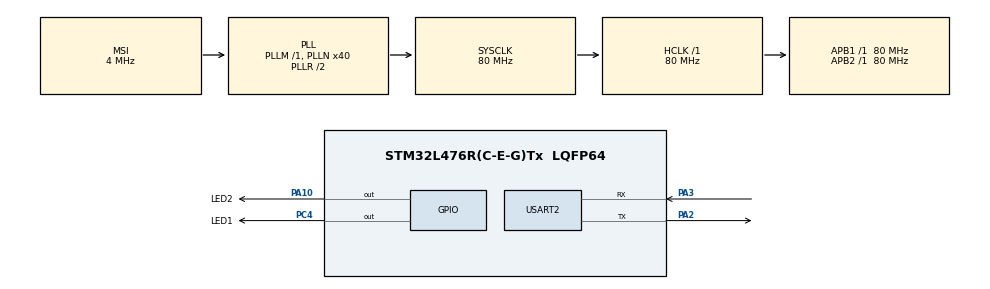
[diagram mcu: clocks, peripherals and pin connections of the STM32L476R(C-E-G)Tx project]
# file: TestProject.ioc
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FREERTOS.Tasks01=defaultTask,24,128,StartDefaultTask,Default,NULL,Dynamic,NULL,NULL;Task2,24,128,Task2_init,Default,NULL,Dynamic,NULL,NULL
FREERTOS.configUSE_NEWLIB_REENTRANT=1
Mcu.Family=STM32L4
Mcu.Name=STM32L476R(C-E-G)Tx
Mcu.Package=LQFP64
NVIC.PriorityGroup=NVIC_PRIORITYGROUP_4
NVIC.TIM6_DAC_IRQn=true\:15\:0\:false\:false\:true\:false\:false\:true\:true
NVIC.TimeBase=TIM6_DAC_IRQn
NVIC.TimeBaseIP=TIM6
PA10.GPIO_Label=LED2
PA10.Signal=GPIO_Output
PA13\ (JTMS-SWDIO).Mode=Serial_Wire
PA13\ (JTMS-SWDIO).Signal=SYS_JTMS-SWDIO
PA14\ (JTCK-SWCLK).Mode=Serial_Wire
PA14\ (JTCK-SWCLK).Signal=SYS_JTCK-SWCLK
PA2.Mode=Asynchronous
PA2.Signal=USART2_TX
PA3.Mode=Asynchronous
PA3.Signal=USART2_RX
PC4.GPIO_Label=LED1
PC4.Signal=GPIO_Output
ProjectManager.HeapSize=0x200
ProjectManager.StackSize=0x400
ProjectManager.TargetToolchain=STM32CubeIDE
RCC.AHBFreq_Value=80000000
RCC.APB1Freq_Value=80000000
RCC.APB1TimFreq_Value=80000000
RCC.APB2Freq_Value=80000000
RCC.APB2TimFreq_Value=80000000
RCC.CortexFreq_Value=80000000
RCC.HCLKFreq_Value=80000000
RCC.HSI_VALUE=16000000
RCC.LSE_VALUE=32768
RCC.MSI_VALUE=4000000
RCC.PLLN=40
RCC.SYSCLKFreq_VALUE=80000000
RCC.SYSCLKSource=RCC_SYSCLKSOURCE_PLLCLK
RCC.VCOOutputFreq_Value=160000000
USART2.VirtualMode-Asynchronous=VM_ASYNC
VP_FREERTOS_VS_CMSIS_V2.Mode=CMSIS_V2
VP_SYS_VS_tim6.Mode=TIM6
board=custom

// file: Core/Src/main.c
/* USER CODE BEGIN Header */
/**
  ******************************************************************************
  * @file           : main.c
  * @brief          : Main program body
  ******************************************************************************
  * @attention
  *
  * Copyright (c) 2024 STMicroelectronics.
  * All rights reserved.
  *
  * This software is licensed under terms that can be found in the LICENSE file
  * in the root directory of this software component.
  * If no LICENSE file comes with this software, it is provided AS-IS.
  *
  ******************************************************************************
  */
/* USER CODE END Header */
#include "main.h"
#include "cmsis_os.h"

UART_HandleTypeDef huart2;

/* Definitions for defaultTask */
osThreadId_t defaultTaskHandle;
const osThreadAttr_t defaultTask_attributes = {
  .name = "defaultTask",
  .stack_size = 128 * 4,
  .priority = (osPriority_t) osPriorityNormal,
};
/* Definitions for Task2 */
osThreadId_t Task2Handle;
const osThreadAttr_t Task2_attributes = {
  .name = "Task2",
  .stack_size = 128 * 4,
  .priority = (osPriority_t) osPriorityAboveNormal,
};

/* Definition for Task3 */
osThreadId_t Task3Handle;
const osThreadAttr_t Task3_attributes = {
	.name = "Task3",
	.stack_size = 128 * 4,
	.priority = (osPriority_t) osPriorityBelowNormal,
};

void SystemClock_Config(void);
static void MX_GPIO_Init(void);
static void MX_USART2_UART_Init(void);
void StartDefaultTask(void *argument);
void Task2_init(void *argument);
void Task3_init(void *argument);

/* USER CODE BEGIN 0 */
uint8_t message_deftask[] = "Deftask says Hello\r\n";
uint8_t message_task2[] = "Task1 says Hello\r\n";
uint8_t message_task3[] = "Task2 says Hello\r\n";

void send_deftask(void)
{
	HAL_UART_Transmit(&huart2, message_deftask, sizeof(message_deftask), HAL_MAX_DELAY);
}

void send_task2(void)
{
	HAL_UART_Transmit(&huart2, message_task2, sizeof(message_task2), HAL_MAX_DELAY);
}

void send_task3(void)
{
	HAL_UART_Transmit(&huart2, message_task3, sizeof(message_task3), HAL_MAX_DELAY);
}

/* USER CODE END 0 */

int main(void)
{

  /* MCU Configuration--------------------------------------------------------*/

  /* Reset of all peripherals, Initializes the Flash interface and the Systick. */
  HAL_Init();

  /* USER CODE BEGIN Init */
printf("Starting...");
  /* USER CODE END Init */

  /* Configure the system clock */
  SystemClock_Config();

  /* Initialize all configured peripherals */
  MX_GPIO_Init();
  MX_USART2_UART_Init();

  /* Init scheduler */
  osKernelInitialize();

  /* Create the thread(s) */
  /* creation of defaultTask */
  defaultTaskHandle = osThreadNew(StartDefaultTask, NULL, &defaultTask_attributes);

  /* creation of Task2 */
  Task2Handle = osThreadNew(Task2_init, NULL, &Task2_attributes);

  /* creation of Task3 */
  Task3Handle = osThreadNew(Task3_init , NULL, &Task3_attributes);

  /* Start scheduler */
  osKernelStart();

  /* We should never get here as control is now taken by the scheduler */
  /* Infinite loop */
  while (1)
  {

  }
}

void SystemClock_Config(void)
{
  RCC_OscInitTypeDef RCC_OscInitStruct = {0};
  RCC_ClkInitTypeDef RCC_ClkInitStruct = {0};

  /** Configure the main internal regulator output voltage
  */
  if (HAL_PWREx_ControlVoltageScaling(PWR_REGULATOR_VOLTAGE_SCALE1) != HAL_OK)
  {
    Error_Handler();
  }

  /** Initializes the RCC Oscillators according to the specified parameters
  * in the RCC_OscInitTypeDef structure.
  */
  RCC_OscInitStruct.OscillatorType = RCC_OSCILLATORTYPE_MSI;
  RCC_OscInitStruct.MSIState = RCC_MSI_ON;
  RCC_OscInitStruct.MSICalibrationValue = 0;
  RCC_OscInitStruct.MSIClockRange = RCC_MSIRANGE_6;
  RCC_OscInitStruct.PLL.PLLState = RCC_PLL_ON;
  RCC_OscInitStruct.PLL.PLLSource = RCC_PLLSOURCE_MSI;
  RCC_OscInitStruct.PLL.PLLM = 1;
  RCC_OscInitStruct.PLL.PLLN = 40;
  RCC_OscInitStruct.PLL.PLLP = RCC_PLLP_DIV7;
  RCC_OscInitStruct.PLL.PLLQ = RCC_PLLQ_DIV2;
  RCC_OscInitStruct.PLL.PLLR = RCC_PLLR_DIV2;
  if (HAL_RCC_OscConfig(&RCC_OscInitStruct) != HAL_OK)
  {
    Error_Handler();
  }

  /** Initializes the CPU, AHB and APB buses clocks
  */
  RCC_ClkInitStruct.ClockType = RCC_CLOCKTYPE_HCLK|RCC_CLOCKTYPE_SYSCLK
                              |RCC_CLOCKTYPE_PCLK1|RCC_CLOCKTYPE_PCLK2;
  RCC_ClkInitStruct.SYSCLKSource = RCC_SYSCLKSOURCE_PLLCLK;
  RCC_ClkInitStruct.AHBCLKDivider = RCC_SYSCLK_DIV1;
  RCC_ClkInitStruct.APB1CLKDivider = RCC_HCLK_DIV1;
  RCC_ClkInitStruct.APB2CLKDivider = RCC_HCLK_DIV1;

  if (HAL_RCC_ClockConfig(&RCC_ClkInitStruct, FLASH_LATENCY_4) != HAL_OK)
  {
    Error_Handler();
  }
}

static void MX_USART2_UART_Init(void)
{

  huart2.Instance = USART2;
  huart2.Init.BaudRate = 115200;
  huart2.Init.WordLength = UART_WORDLENGTH_8B;
  huart2.Init.StopBits = UART_STOPBITS_1;
  huart2.Init.Parity = UART_PARITY_NONE;
  huart2.Init.Mode = UART_MODE_TX_RX;
  huart2.Init.HwFlowCtl = UART_HWCONTROL_NONE;
  huart2.Init.OverSampling = UART_OVERSAMPLING_16;
  huart2.Init.OneBitSampling = UART_ONE_BIT_SAMPLE_DISABLE;
  huart2.AdvancedInit.AdvFeatureInit = UART_ADVFEATURE_NO_INIT;
  if (HAL_UART_Init(&huart2) != HAL_OK)
  {
    Error_Handler();
  }

}

static void MX_GPIO_Init(void)
{
  GPIO_InitTypeDef GPIO_InitStruct = {0};

  /* GPIO Ports Clock Enable */
  __HAL_RCC_GPIOA_CLK_ENABLE();
  __HAL_RCC_GPIOC_CLK_ENABLE();

  /*Configure GPIO pin Output Level */
  HAL_GPIO_WritePin(LED1_GPIO_Port, LED1_Pin, GPIO_PIN_RESET);

  /*Configure GPIO pin Output Level */
  HAL_GPIO_WritePin(LED2_GPIO_Port, LED2_Pin, GPIO_PIN_RESET);

  /*Configure GPIO pin : LED1_Pin */
  GPIO_InitStruct.Pin = LED1_Pin;
  GPIO_InitStruct.Mode = GPIO_MODE_OUTPUT_PP;
  GPIO_InitStruct.Pull = GPIO_NOPULL;
  GPIO_InitStruct.Speed = GPIO_SPEED_FREQ_LOW;
  HAL_GPIO_Init(LED1_GPIO_Port, &GPIO_InitStruct);

  /*Configure GPIO pin : LED2_Pin */
  GPIO_InitStruct.Pin = LED2_Pin;
  GPIO_InitStruct.Mode = GPIO_MODE_OUTPUT_PP;
  GPIO_InitStruct.Pull = GPIO_NOPULL;
  GPIO_InitStruct.Speed = GPIO_SPEED_FREQ_LOW;
  HAL_GPIO_Init(LED2_GPIO_Port, &GPIO_InitStruct);

}

void StartDefaultTask(void *argument)
{
  /* USER CODE BEGIN 5 */
  /* Infinite loop */
  for(;;)
  {
	send_deftask();
    osDelay(1000);
  }
  /* USER CODE END 5 */
}

void Task2_init(void *argument)
{
  /* USER CODE BEGIN Task2_init */
  /* Infinite loop */
  for(;;)
  {
	send_task2();
	osDelay(1000);
  }
  /* USER CODE END Task2_init */
}

void Task3_init(void *argument)
{
	for(;;)
	{
		send_task3();
		osDelay(1000);
	}
}

void HAL_TIM_PeriodElapsedCallback(TIM_HandleTypeDef *htim)
{
  if (htim->Instance == TIM6) {
    HAL_IncTick();
  }
}

void Error_Handler(void)
{
  __disable_irq();
  while (1)
  {
  }
}
